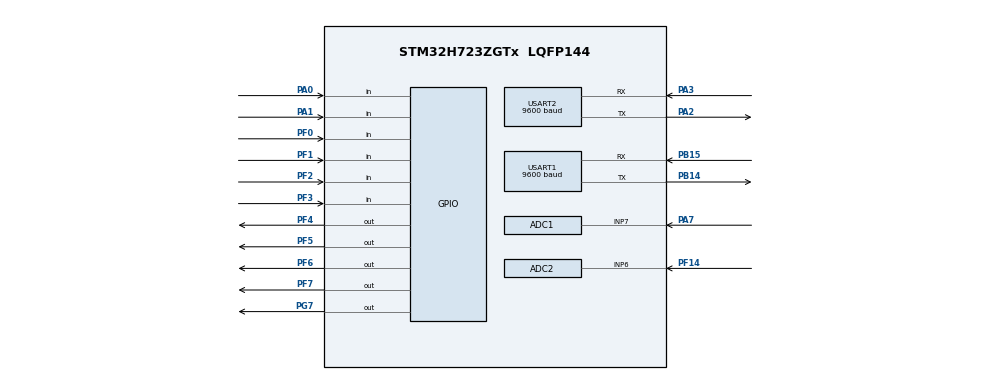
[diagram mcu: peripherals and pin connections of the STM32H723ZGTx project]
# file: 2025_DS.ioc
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ADC1.Channel-1\#ChannelRegularConversion=ADC_CHANNEL_7
ADC1.NbrOfConversionFlag=1
ADC1.OffsetNumber-1\#ChannelRegularConversion=ADC_OFFSET_NONE
ADC1.OffsetSignedSaturation-1\#ChannelRegularConversion=DISABLE
ADC1.Rank-1\#ChannelRegularConversion=1
ADC1.SamplingTime-1\#ChannelRegularConversion=ADC_SAMPLETIME_64CYCLES_5
ADC1.master=1
ADC2.Channel-1\#ChannelRegularConversion=ADC_CHANNEL_6
ADC2.NbrOfConversionFlag=1
ADC2.OffsetNumber-1\#ChannelRegularConversion=ADC_OFFSET_NONE
ADC2.OffsetSignedSaturation-1\#ChannelRegularConversion=DISABLE
ADC2.Rank-1\#ChannelRegularConversion=1
ADC2.SamplingTime-1\#ChannelRegularConversion=ADC_SAMPLETIME_64CYCLES_5
CORTEX_M7.default_mode_Activation=1
Mcu.Family=STM32H7
Mcu.Name=STM32H723ZGTx
Mcu.Package=LQFP144
NVIC.PriorityGroup=NVIC_PRIORITYGROUP_4
NVIC.TIM1_BRK_IRQn=true\:1\:0\:true\:false\:true\:true\:true\:true
NVIC.TIM1_CC_IRQn=true\:1\:0\:true\:false\:true\:true\:true\:true
NVIC.TIM1_TRG_COM_IRQn=true\:1\:0\:true\:false\:true\:true\:true\:true
NVIC.TIM1_UP_IRQn=true\:1\:0\:true\:false\:true\:true\:true\:true
NVIC.USART2_IRQn=true\:0\:0\:false\:false\:true\:true\:true\:true
PA0.GPIO_PuPd=GPIO_PULLUP
PA0.Signal=GPIO_Input
PA1.GPIO_PuPd=GPIO_PULLUP
PA1.Signal=GPIO_Input
PA13(JTMS/SWDIO).Mode=Serial_Wire
PA13(JTMS/SWDIO).Signal=DEBUG_JTMS-SWDIO
PA14(JTCK/SWCLK).Mode=Serial_Wire
PA14(JTCK/SWCLK).Signal=DEBUG_JTCK-SWCLK
PA2.Mode=Asynchronous
PA2.Signal=USART2_TX
PA3.Mode=Asynchronous
PA3.Signal=USART2_RX
PA7.Signal=ADCx_INP7
PB14.Mode=Asynchronous
PB14.Signal=USART1_TX
PB15.Mode=Asynchronous
PB15.Signal=USART1_RX
PF0.GPIO_Mode=GPIO_MODE_INPUT
PF0.GPIO_PuPd=GPIO_PULLUP
PF0.Signal=GPIO_Input
PF1.GPIO_Mode=GPIO_MODE_INPUT
PF1.GPIO_PuPd=GPIO_PULLUP
PF1.Signal=GPIO_Input
PF14.Mode=IN6-Single-Ended
PF14.Signal=ADC2_INP6
PF2.GPIO_Mode=GPIO_MODE_INPUT
PF2.GPIO_PuPd=GPIO_PULLUP
PF2.Signal=GPIO_Input
PF3.GPIO_Mode=GPIO_MODE_INPUT
PF3.GPIO_PuPd=GPIO_PULLUP
PF3.Signal=GPIO_Input
PF4.Signal=GPIO_Output
PF5.Signal=GPIO_Output
PF6.Signal=GPIO_Output
PF7.Signal=GPIO_Output
PG7.PinState=GPIO_PIN_RESET
PG7.Signal=GPIO_Output
PH0-OSC_IN.Mode=HSE-External-Oscillator
PH0-OSC_IN.Signal=RCC_OSC_IN
PH1-OSC_OUT.Mode=HSE-External-Oscillator
PH1-OSC_OUT.Signal=RCC_OSC_OUT
ProjectManager.HeapSize=0x200
ProjectManager.StackSize=0x400
ProjectManager.TargetToolchain=MDK-ARM V5.32
RCC.ADCFreq_Value=129000000
RCC.APB1Freq_Value=100000000
RCC.APB2Freq_Value=100000000
RCC.APB3Freq_Value=100000000
RCC.APB4Freq_Value=100000000
RCC.CortexFreq_Value=200000000
RCC.D1PPRE=RCC_APB3_DIV2
RCC.D2PPRE1=RCC_APB1_DIV2
RCC.D2PPRE2=RCC_APB2_DIV2
RCC.D3PPRE=RCC_APB4_DIV2
RCC.DIVM1=4
RCC.DIVN1=12
RCC.DIVP1=1
RCC.HCLKFreq_Value=200000000
RCC.PLL2FRACN=0
RCC.PLL3FRACN=0
RCC.PLLFRACN=4096
RCC.SYSCLKFreq_VALUE=200000000
RCC.SYSCLKSource=RCC_SYSCLKSOURCE_PLLCLK
RCC.USBFreq_Value=100000000
SH.ADCx_INP7.0=ADC1_INP7,IN7-Single-Ended
TIM1.Period=1000  - 1
TIM1.Prescaler=2000 - 1
USART1.BaudRate=9600
USART1.VirtualMode-Asynchronous=VM_ASYNC
USART2.BaudRate=9600
USART2.VirtualMode-Asynchronous=VM_ASYNC
VP_MEMORYMAP_VS_MEMORYMAP.Mode=CurAppReg
VP_TIM1_VS_ClockSourceINT.Mode=Internal
board=custom

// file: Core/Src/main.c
/* USER CODE BEGIN Header */
/**
  ******************************************************************************
  * @file           : main.c
  * @brief          : Main program body
  ******************************************************************************
  * @attention
  *
  * Copyright (c) 2025 STMicroelectronics.
  * All rights reserved.
  *
  * This software is licensed under terms that can be found in the LICENSE file
  * in the root directory of this software component.
  * If no LICENSE file comes with this software, it is provided AS-IS.
  *
  ******************************************************************************
  */
/* USER CODE END Header */
#include "main.h"
#include "adc.h"
#include "tim.h"
#include "usart.h"
#include "gpio.h"

/* USER CODE BEGIN Includes */
#include "mybsp.h"
/* USER CODE END Includes */

void SystemClock_Config(void);
void PeriphCommonClock_Config(void);
static void MPU_Config(void);

int main(void)
{

  /* MPU Configuration--------------------------------------------------------*/
  MPU_Config();

  /* MCU Configuration--------------------------------------------------------*/

  /* Reset of all peripherals, Initializes the Flash interface and the Systick. */
  HAL_Init();

  /* Configure the system clock */
  SystemClock_Config();

  /* Configure the peripherals common clocks */
  PeriphCommonClock_Config();

  /* Initialize all configured peripherals */
  MX_GPIO_Init();
  MX_USART1_UART_Init();
  MX_USART2_UART_Init();
  MX_ADC1_Init();
  MX_ADC2_Init();
  MX_TIM1_Init();
  /* USER CODE BEGIN 2 */
	peri_init();

  /* USER CODE END 2 */

  /* Infinite loop */
  /* USER CODE BEGIN WHILE */
  while (1)
  {
		task_start();
    /* USER CODE END WHILE */

  }
}

void SystemClock_Config(void)
{
  RCC_OscInitTypeDef RCC_OscInitStruct = {0};
  RCC_ClkInitTypeDef RCC_ClkInitStruct = {0};

  /** Supply configuration update enable
  */
  HAL_PWREx_ConfigSupply(PWR_LDO_SUPPLY);

  /** Configure the main internal regulator output voltage
  */
  __HAL_PWR_VOLTAGESCALING_CONFIG(PWR_REGULATOR_VOLTAGE_SCALE1);

  while(!__HAL_PWR_GET_FLAG(PWR_FLAG_VOSRDY)) {}

  /** Initializes the RCC Oscillators according to the specified parameters
  * in the RCC_OscInitTypeDef structure.
  */
  RCC_OscInitStruct.OscillatorType = RCC_OSCILLATORTYPE_HSI;
  RCC_OscInitStruct.HSIState = RCC_HSI_DIV1;
  RCC_OscInitStruct.HSICalibrationValue = 64;
  RCC_OscInitStruct.PLL.PLLState = RCC_PLL_ON;
  RCC_OscInitStruct.PLL.PLLSource = RCC_PLLSOURCE_HSI;
  RCC_OscInitStruct.PLL.PLLM = 4;
  RCC_OscInitStruct.PLL.PLLN = 12;
  RCC_OscInitStruct.PLL.PLLP = 1;
  RCC_OscInitStruct.PLL.PLLQ = 2;
  RCC_OscInitStruct.PLL.PLLR = 2;
  RCC_OscInitStruct.PLL.PLLRGE = RCC_PLL1VCIRANGE_3;
  RCC_OscInitStruct.PLL.PLLVCOSEL = RCC_PLL1VCOWIDE;
  RCC_OscInitStruct.PLL.PLLFRACN = 4096;
  if (HAL_RCC_OscConfig(&RCC_OscInitStruct) != HAL_OK)
  {
    Error_Handler();
  }

  /** Initializes the CPU, AHB and APB buses clocks
  */
  RCC_ClkInitStruct.ClockType = RCC_CLOCKTYPE_HCLK|RCC_CLOCKTYPE_SYSCLK
                              |RCC_CLOCKTYPE_PCLK1|RCC_CLOCKTYPE_PCLK2
                              |RCC_CLOCKTYPE_D3PCLK1|RCC_CLOCKTYPE_D1PCLK1;
  RCC_ClkInitStruct.SYSCLKSource = RCC_SYSCLKSOURCE_PLLCLK;
  RCC_ClkInitStruct.SYSCLKDivider = RCC_SYSCLK_DIV1;
  RCC_ClkInitStruct.AHBCLKDivider = RCC_HCLK_DIV1;
  RCC_ClkInitStruct.APB3CLKDivider = RCC_APB3_DIV2;
  RCC_ClkInitStruct.APB1CLKDivider = RCC_APB1_DIV2;
  RCC_ClkInitStruct.APB2CLKDivider = RCC_APB2_DIV2;
  RCC_ClkInitStruct.APB4CLKDivider = RCC_APB4_DIV2;

  if (HAL_RCC_ClockConfig(&RCC_ClkInitStruct, FLASH_LATENCY_2) != HAL_OK)
  {
    Error_Handler();
  }
}

void PeriphCommonClock_Config(void)
{
  RCC_PeriphCLKInitTypeDef PeriphClkInitStruct = {0};

  /** Initializes the peripherals clock
  */
  PeriphClkInitStruct.PeriphClockSelection = RCC_PERIPHCLK_ADC;
  PeriphClkInitStruct.PLL2.PLL2M = 32;
  PeriphClkInitStruct.PLL2.PLL2N = 129;
  PeriphClkInitStruct.PLL2.PLL2P = 2;
  PeriphClkInitStruct.PLL2.PLL2Q = 2;
  PeriphClkInitStruct.PLL2.PLL2R = 2;
  PeriphClkInitStruct.PLL2.PLL2RGE = RCC_PLL2VCIRANGE_1;
  PeriphClkInitStruct.PLL2.PLL2VCOSEL = RCC_PLL2VCOWIDE;
  PeriphClkInitStruct.PLL2.PLL2FRACN = 0;
  PeriphClkInitStruct.AdcClockSelection = RCC_ADCCLKSOURCE_PLL2;
  if (HAL_RCCEx_PeriphCLKConfig(&PeriphClkInitStruct) != HAL_OK)
  {
    Error_Handler();
  }
}

 /* MPU Configuration */

void MPU_Config(void)
{
  MPU_Region_InitTypeDef MPU_InitStruct = {0};

  /* Disables the MPU */
  HAL_MPU_Disable();

  /** Initializes and configures the Region and the memory to be protected
  */
  MPU_InitStruct.Enable = MPU_REGION_ENABLE;
  MPU_InitStruct.Number = MPU_REGION_NUMBER0;
  MPU_InitStruct.BaseAddress = 0x0;
  MPU_InitStruct.Size = MPU_REGION_SIZE_4GB;
  MPU_InitStruct.SubRegionDisable = 0x87;
  MPU_InitStruct.TypeExtField = MPU_TEX_LEVEL0;
  MPU_InitStruct.AccessPermission = MPU_REGION_NO_ACCESS;
  MPU_InitStruct.DisableExec = MPU_INSTRUCTION_ACCESS_DISABLE;
  MPU_InitStruct.IsShareable = MPU_ACCESS_SHAREABLE;
  MPU_InitStruct.IsCacheable = MPU_ACCESS_NOT_CACHEABLE;
  MPU_InitStruct.IsBufferable = MPU_ACCESS_NOT_BUFFERABLE;

  HAL_MPU_ConfigRegion(&MPU_InitStruct);
  /* Enables the MPU */
  HAL_MPU_Enable(MPU_PRIVILEGED_DEFAULT);

}

void Error_Handler(void)
{
  __disable_irq();
  while (1)
  {
  }
}
